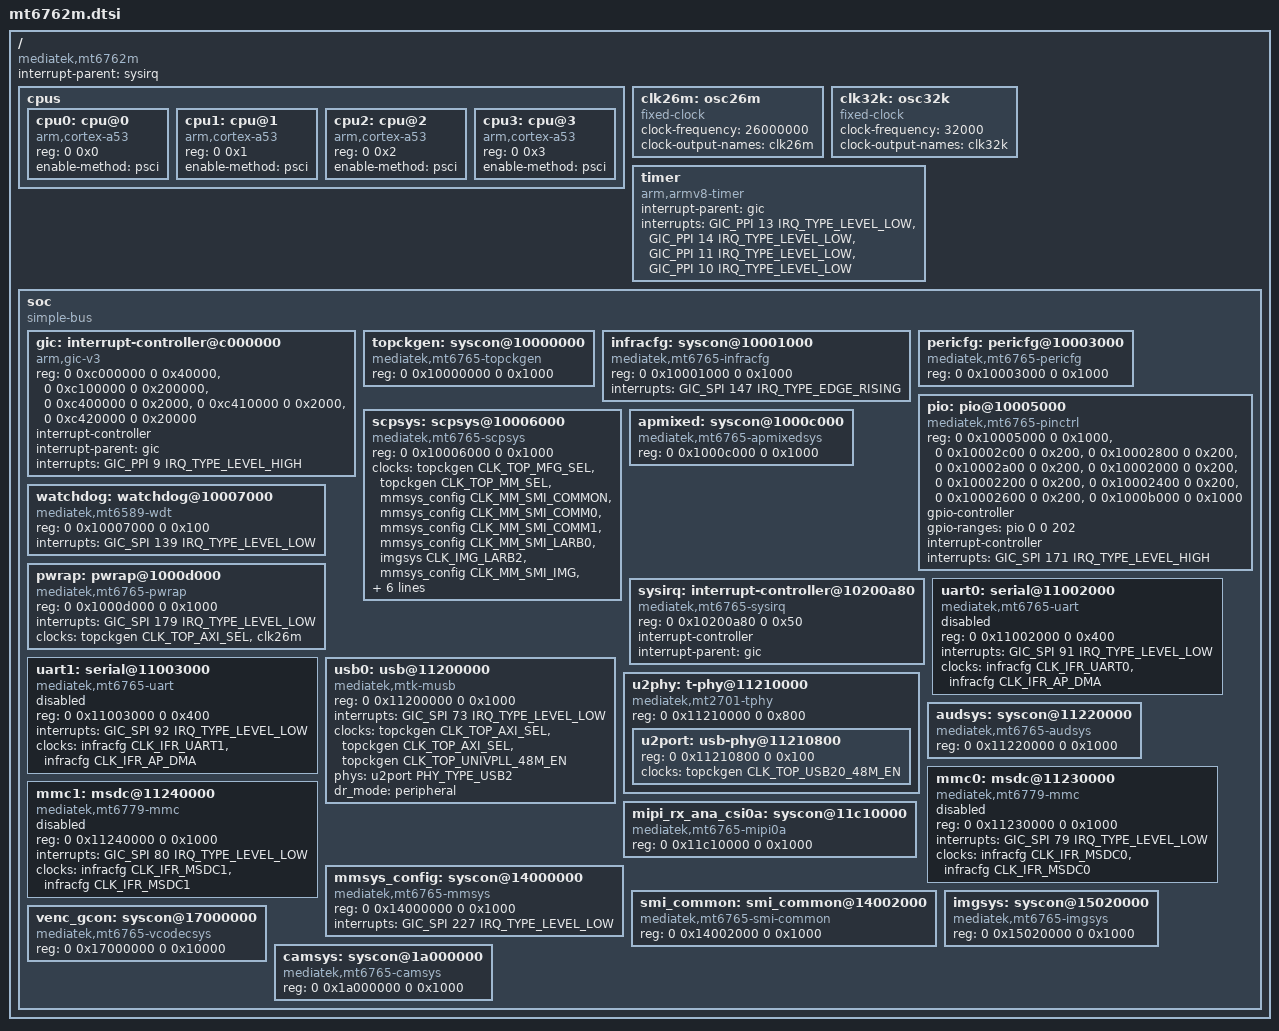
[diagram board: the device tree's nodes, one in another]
// SPDX-License-Identifier: GPL-2.0

#include <dt-bindings/interrupt-controller/irq.h>
#include <dt-bindings/interrupt-controller/arm-gic.h>
#include <dt-bindings/clock/mt6765-clk.h>
#include <dt-bindings/thermal/thermal.h>
#include <dt-bindings/phy/phy.h>

/ {
	#address-cells = <2>;
	#size-cells = <2>;
	compatible = "mediatek,mt6762m", "mediatek,mt6765";
	interrupt-parent = <&sysirq>;

	#if 0 /* i don't use the ATF right now ... */
	psci {
		compatible = "arm,psci-0.2";
		method = "smc";
	};
	#endif

	cpus {
		#address-cells = <2>;
		#size-cells = <0>;

		cpu0: cpu@0 {
			device_type = "cpu";
			compatible = "arm,cortex-a53";
			reg = <0 0x0>;
			enable-method = "psci";
		};

		cpu1: cpu@1 {
			device_type = "cpu";
			compatible = "arm,cortex-a53";
			reg = <0 0x1>;
			enable-method = "psci";
		};

		cpu2: cpu@2 {
			device_type = "cpu";
			compatible = "arm,cortex-a53";
			reg = <0 0x2>;
			enable-method = "psci";
		};

		cpu3: cpu@3 {
			device_type = "cpu";
			compatible = "arm,cortex-a53";
			reg = <0 0x3>;
			enable-method = "psci";
		};
	};

	clk26m: osc26m {
		compatible = "fixed-clock";
		clock-frequency = <26000000>;
		#clock-cells = <0>;
		clock-output-names = "clk26m";
	};

	clk32k: osc32k {
		compatible = "fixed-clock";
		clock-frequency = <32000>;
		#clock-cells = <0>;
		clock-output-names = "clk32k";
	};

	timer {
		compatible = "arm,armv8-timer";
		interrupt-parent = <&gic>;
		interrupts = <GIC_PPI 13 IRQ_TYPE_LEVEL_LOW>,
			     <GIC_PPI 14 IRQ_TYPE_LEVEL_LOW>,
			     <GIC_PPI 11 IRQ_TYPE_LEVEL_LOW>,
			     <GIC_PPI 10 IRQ_TYPE_LEVEL_LOW>;
	};

	soc {
		#address-cells = <2>;
		#size-cells = <2>;
		compatible = "simple-bus";
		ranges;

		gic: interrupt-controller@c000000 {
			compatible = "arm,gic-v3";
			reg = <0 0xc000000 0 0x40000>,
			      <0 0xc100000 0 0x200000>,
			      <0 0xc400000 0 0x2000>,
			      <0 0xc410000 0 0x2000>,
			      <0 0xc420000 0 0x20000>;
			interrupt-controller;
			#interrupt-cells = <3>;
			interrupt-parent = <&gic>;
			interrupts = <GIC_PPI 9 IRQ_TYPE_LEVEL_HIGH>;
		};

		topckgen: syscon@10000000 {
			compatible = "mediatek,mt6765-topckgen", "syscon";
			reg = <0 0x10000000 0 0x1000>;
			#clock-cells = <1>;
		};

		infracfg: syscon@10001000 {
			compatible = "mediatek,mt6765-infracfg", "syscon";
			reg = <0 0x10001000 0 0x1000>;
			interrupts = <GIC_SPI 147 IRQ_TYPE_EDGE_RISING>;
			#clock-cells = <1>;
		};

		pericfg: pericfg@10003000 {
			compatible = "mediatek,mt6765-pericfg", "syscon";
			reg = <0 0x10003000 0 0x1000>;
		};

		pio: pio@10005000 {
			compatible = "mediatek,mt6765-pinctrl";
			reg = <0 0x10005000 0 0x1000>,
			      <0 0x10002c00 0 0x200>,
			      <0 0x10002800 0 0x200>,
			      <0 0x10002a00 0 0x200>,
			      <0 0x10002000 0 0x200>,
			      <0 0x10002200 0 0x200>,
			      <0 0x10002400 0 0x200>,
			      <0 0x10002600 0 0x200>,
			      <0 0x1000b000 0 0x1000>;
			reg-names = "iocfg0", "iocfg1", "iocfg2", "iocfg3",
				    "iocfg4", "iocfg5", "iocfg6", "iocfg7",
				    "eint";
			gpio-controller;
			#gpio-cells = <2>;
			gpio-ranges = <&pio 0 0 202>;
			interrupt-controller;
			#interrupt-cells = <2>;
			interrupts = <GIC_SPI 171 IRQ_TYPE_LEVEL_HIGH>;
		};

		scpsys: scpsys@10006000 {
			compatible = "mediatek,mt6765-scpsys";
			reg = <0 0x10006000 0 0x1000>;
			#power-domain-cells = <1>;
			clocks = <&topckgen CLK_TOP_MFG_SEL>,
				 <&topckgen CLK_TOP_MM_SEL>,
				 <&mmsys_config CLK_MM_SMI_COMMON>,
				 <&mmsys_config CLK_MM_SMI_COMM0>,
				 <&mmsys_config CLK_MM_SMI_COMM1>,
				 <&mmsys_config CLK_MM_SMI_LARB0>,
				 <&imgsys CLK_IMG_LARB2>,
				 <&mmsys_config CLK_MM_SMI_IMG>,
				 <&camsys CLK_CAM_LARB3>,
				 <&camsys CLK_CAM_DFP_VAD>,
				 <&camsys CLK_CAM>,
				 <&camsys CLK_CAM_CCU>,
				 <&mmsys_config CLK_MM_SMI_CAM>;
			clock-names = "mfg", "mm",
				      "mm-0", "mm-1", "mm-2", "mm-3",
				      "isp-0", "isp-1", "cam-0", "cam-1",
				      "cam-2", "cam-3", "cam-4";
			infracfg = <&infracfg>;
			smi_comm = <&smi_common>;
		};

		watchdog: watchdog@10007000 {
			compatible = "mediatek,mt6589-wdt";
			reg = <0 0x10007000 0 0x100>;
			interrupts = <GIC_SPI 139 IRQ_TYPE_LEVEL_LOW>;
		};

		pwrap: pwrap@1000d000 {
			compatible = "mediatek,mt6765-pwrap";
			reg = <0 0x1000d000 0 0x1000>;
			reg-names = "pwrap";
			interrupts = <GIC_SPI 179 IRQ_TYPE_LEVEL_LOW>;
			clocks = <&topckgen CLK_TOP_AXI_SEL>,
				 <&clk26m>;
			clock-names = "wrap", "spi";
		};

		apmixed: syscon@1000c000 {
			compatible = "mediatek,mt6765-apmixedsys", "syscon";
			reg = <0 0x1000c000 0 0x1000>;
			#clock-cells = <1>;
		};

		sysirq: interrupt-controller@10200a80 {
			compatible = "mediatek,mt6765-sysirq",
				     "mediatek,mt6577-sysirq";
			reg = <0 0x10200a80 0 0x50>;
			interrupt-controller;
			#interrupt-cells = <3>;
			interrupt-parent = <&gic>;
		};

		uart0: serial@11002000 {
			compatible = "mediatek,mt6765-uart",
				     "mediatek,mt6577-uart";
			reg = <0 0x11002000 0 0x400>;
			interrupts = <GIC_SPI 91 IRQ_TYPE_LEVEL_LOW>;
			clocks = <&infracfg CLK_IFR_UART0>,
				 <&infracfg CLK_IFR_AP_DMA>;
			clock-names = "baud", "bus";
			status = "disabled";
		};

		uart1: serial@11003000 {
			compatible = "mediatek,mt6765-uart",
				     "mediatek,mt6577-uart";
			reg = <0 0x11003000 0 0x400>;
			interrupts = <GIC_SPI 92 IRQ_TYPE_LEVEL_LOW>;
			clocks = <&infracfg CLK_IFR_UART1>,
				 <&infracfg CLK_IFR_AP_DMA>;
			clock-names = "baud", "bus";
			status = "disabled";
		};

		usb0: usb@11200000 {
			compatible = "mediatek,mtk-musb";
			reg = <0 0x11200000 0 0x1000>;
			interrupts = <GIC_SPI 73 IRQ_TYPE_LEVEL_LOW>;
			interrupt-names = "mc";
			clocks = <&topckgen CLK_TOP_AXI_SEL>,
				 <&topckgen CLK_TOP_AXI_SEL>,
				 <&topckgen CLK_TOP_UNIVPLL_48M_EN>;
			clock-names = "main", "mcu", "univpll";
			phys = <&u2port PHY_TYPE_USB2>;
			dr_mode = "peripheral";
		};

		/* TODO the host mode doesn't seem to work */
		u2phy: t-phy@11210000 {
			compatible = "mediatek,mt2701-tphy",
				     "mediatek,generic-tphy-v1";
			reg = <0 0x11210000 0 0x800>;
			#address-cells = <2>;
			#size-cells = <2>;
			ranges;

			u2port: usb-phy@11210800 {
				reg = <0 0x11210800 0 0x100>;
				clocks = <&topckgen CLK_TOP_USB20_48M_EN>;
				clock-names = "ref";
				#phy-cells = <1>;
			};
		};

		audsys: syscon@11220000 {
			compatible = "mediatek,mt6765-audsys", "syscon";
			reg = <0 0x11220000 0 0x1000>;
			#clock-cells = <1>;
		};

		mmc0: msdc@11230000 {
			compatible = "mediatek,mt6779-mmc";
			reg = <0 0x11230000 0 0x1000>;
			interrupts = <GIC_SPI 79 IRQ_TYPE_LEVEL_LOW>;
			clocks = <&infracfg CLK_IFR_MSDC0>,
				 <&infracfg CLK_IFR_MSDC0>;
			clock-names = "source", "hclk";
			status = "disabled";
		};

		mmc1: msdc@11240000 {
			compatible = "mediatek,mt6779-mmc";
			reg = <0 0x11240000 0 0x1000>;
			interrupts = <GIC_SPI 80 IRQ_TYPE_LEVEL_LOW>;
			clocks = <&infracfg CLK_IFR_MSDC1>,
				 <&infracfg CLK_IFR_MSDC1>;
			clock-names = "source", "hclk";
			status = "disabled";
		};

		mipi_rx_ana_csi0a: syscon@11c10000 {
			compatible = "mediatek,mt6765-mipi0a", "syscon";
			reg = <0 0x11c10000 0 0x1000>;
			#clock-cells = <1>;
		};

		mmsys_config: syscon@14000000 {
			compatible = "mediatek,mt6765-mmsys", "syscon";
			reg = <0 0x14000000 0 0x1000>;
			interrupts = <GIC_SPI 227 IRQ_TYPE_LEVEL_LOW>;
			#clock-cells = <1>;
		};

		smi_common: smi_common@14002000 {
			compatible = "mediatek,mt6765-smi-common", "syscon";
			reg = <0 0x14002000 0 0x1000>;
		};

		imgsys: syscon@15020000 {
			compatible = "mediatek,mt6765-imgsys", "syscon";
			reg = <0 0x15020000 0 0x1000>;
			#clock-cells = <1>;
		};

		venc_gcon: syscon@17000000 {
			compatible = "mediatek,mt6765-vcodecsys", "syscon";
			reg = <0 0x17000000 0 0x10000>;
			#clock-cells = <1>;
		};

		camsys: syscon@1a000000 {
			compatible = "mediatek,mt6765-camsys", "syscon";
			reg = <0 0x1a000000 0 0x1000>;
			#clock-cells = <1>;
		};
	};
};
